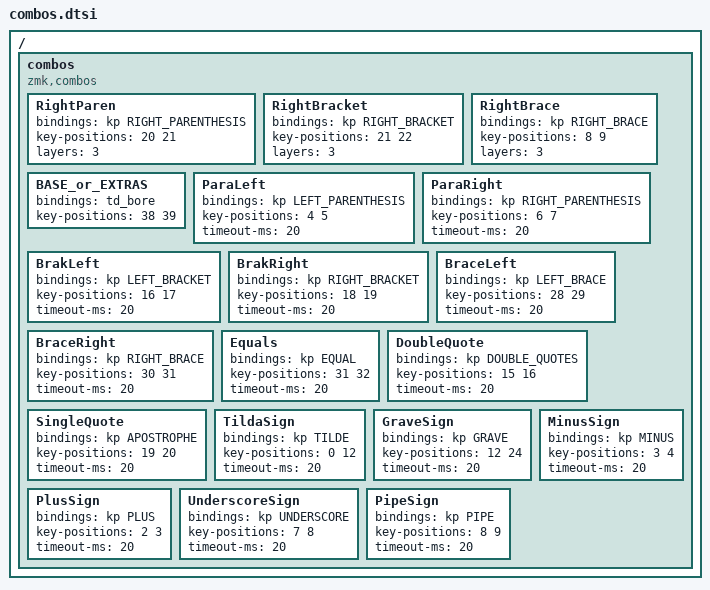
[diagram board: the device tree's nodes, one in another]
/ {
    combos {
        compatible = "zmk,combos";

        RightParen {
            bindings = <&kp RIGHT_PARENTHESIS>;
            key-positions = <20 21>;
            layers = <3>;
        };

        RightBracket {
            bindings = <&kp RIGHT_BRACKET>;
            key-positions = <21 22>;
            layers = <3>;
        };

        RightBrace {
            bindings = <&kp RIGHT_BRACE>;
            key-positions = <8 9>;
            layers = <3>;
        };

        BASE_or_EXTRAS {
            bindings = <&td_bore>;
            key-positions = <38 39>;
        };

        ParaLeft {
            bindings = <&kp LEFT_PARENTHESIS>;
            key-positions = <4 5>;
            timeout-ms = <20>;
        };

        ParaRight {
            bindings = <&kp RIGHT_PARENTHESIS>;
            key-positions = <6 7>;
            timeout-ms = <20>;
        };

        BrakLeft {
            bindings = <&kp LEFT_BRACKET>;
            key-positions = <16 17>;
            timeout-ms = <20>;
        };

        BrakRight {
            bindings = <&kp RIGHT_BRACKET>;
            key-positions = <18 19>;
            timeout-ms = <20>;
        };

        BraceLeft {
            bindings = <&kp LEFT_BRACE>;
            key-positions = <28 29>;
            timeout-ms = <20>;
        };

        BraceRight {
            bindings = <&kp RIGHT_BRACE>;
            key-positions = <30 31>;
            timeout-ms = <20>;
        };

        Equals {
            bindings = <&kp EQUAL>;
            key-positions = <31 32>;
            timeout-ms = <20>;
        };

        DoubleQuote {
            bindings = <&kp DOUBLE_QUOTES>;
            key-positions = <15 16>;
            timeout-ms = <20>;
        };

        SingleQuote {
            bindings = <&kp APOSTROPHE>;
            key-positions = <19 20>;
            timeout-ms = <20>;
        };

        //LangRu {
        //    bindings = <&kp LG(F11)>;
        //    key-positions = <0 1>;
        //    timeout-ms = <20>;
        //};

        //LangUs {
        //   bindings = <&kp LG(F12)>;
        //    key-positions = <10 11>;
        //    timeout-ms = <20>;
        //};

        //LangRuL {
        //    bindings = <&kp LG(F11)>;
        //    key-positions = <36 38>;
        //    timeout-ms = <20>;
        //};

        //LangUsL {
        //    bindings = <&kp LG(F12)>;
        //    key-positions = <39 41>;
        //    timeout-ms = <20>;
        //};

        TildaSign {
            bindings = <&kp TILDE>;
            key-positions = <0 12>;
            timeout-ms = <20>;
        };

        GraveSign {
            bindings = <&kp GRAVE>;
            key-positions = <12 24>;
            timeout-ms = <20>;
        };

        MinusSign {
            bindings = <&kp MINUS>;
            key-positions = <3 4>;
            timeout-ms = <20>;
        };

        PlusSign {
            bindings = <&kp PLUS>;
            key-positions = <2 3>;
            timeout-ms = <20>;
        };

        UnderscoreSign {
            bindings = <&kp UNDERSCORE>;
            key-positions = <7 8>;
            timeout-ms = <20>;
        };

        PipeSign {
            bindings = <&kp PIPE>;
            key-positions = <8 9>;
            timeout-ms = <20>;
        };

    };
};
